# ATtiny828 device description
Architecture: AVR8; Family: tinyAVR
Registers are 8-bit, access not given, no defined reset value unless marked. A register's access mark holds for its fields unless they carry their own. Offsets are from the block's base; [hi:lo] are bit positions; {n}, {i} and the like mark numbered series.

## TC0 (TC8 module) — Timer/Counter, 8-bit
Instances: TC0 0x00
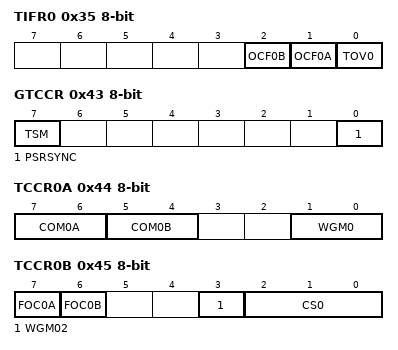
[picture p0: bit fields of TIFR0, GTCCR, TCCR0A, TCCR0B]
0x35 TIFR0 — Timer/Counter0 Interrupt Flag register
  [2] OCF0B — Timer/Counter0 Output Compare Flag 0B
  [1] OCF0A — Timer/Counter0 Output Compare Flag 0A
  [0] TOV0 — Timer/Counter0 Overflow Flag
0x43 GTCCR — General Timer/Counter Control Register
  [7] TSM — Timer/Counter Synchronization Mode
  [0] PSRSYNC — Prescaler Reset Timer/Counter1 and Timer/Counter0
0x44 TCCR0A — Timer/Counter Control Register A
  [7:6] COM0A — Compare Output Mode, Phase Correct PWM Mode
  [5:4] COM0B — Compare Output Mode, Fast PWm
  [1:0] WGM0 — Waveform Generation Mode
0x45 TCCR0B — Timer/Counter Control Register B
  [7] FOC0A — Force Output Compare A
  [6] FOC0B — Force Output Compare B
  [3] WGM02
  [2:0] CS0 — Clock Select
    0=No Clock Source (Stopped); 1=Running, No Prescaling; 2=Running, CLK/8; 3=Running, CLK/64; 4=Running, CLK/256; 5=Running, CLK/1024; 6=Running, ExtClk Tx Falling Edge; 7=Running, ExtClk Tx Rising Edge
0x46 TCNT0 — Timer/Counter0
0x47 OCR0A — Timer/Counter0 Output Compare Register
0x48 OCR0B — Timer/Counter0 Output Compare Register
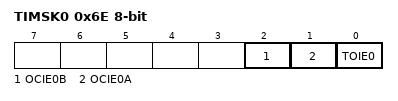
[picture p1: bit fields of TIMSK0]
0x6E TIMSK0 — Timer/Counter0 Interrupt Mask Register
  [2] OCIE0B — Timer/Counter0 Output Compare Match B Interrupt Enable
  [1] OCIE0A — Timer/Counter0 Output Compare Match A Interrupt Enable
  [0] TOIE0 — Timer/Counter0 Overflow Interrupt Enable

## TC1 (TC16 module) — Timer/Counter, 16-bit
Instances: TC1 0x00
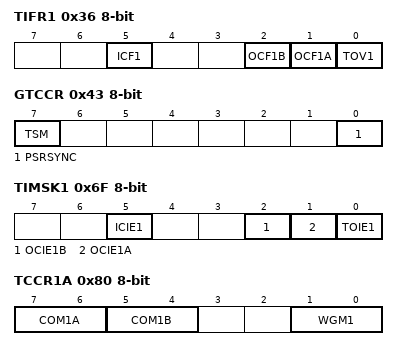
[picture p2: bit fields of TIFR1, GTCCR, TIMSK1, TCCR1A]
0x36 TIFR1 — Timer/Counter Interrupt Flag register
  [5] ICF1 — Input Capture Flag 1
  [2] OCF1B — Output Compare Flag 1B
  [1] OCF1A — Output Compare Flag 1A
  [0] TOV1 — Timer/Counter1 Overflow Flag
0x43 GTCCR — General Timer/Counter Control Register
  [7] TSM — Timer/Counter Synchronization Mode
  [0] PSRSYNC — Prescaler Reset Timer/Counter1 and Timer/Counter0
0x6F TIMSK1 — Timer/Counter Interrupt Mask Register
  [5] ICIE1 — Timer/Counter1 Input Capture Interrupt Enable
  [2] OCIE1B — Timer/Counter1 Output CompareB Match Interrupt Enable
  [1] OCIE1A — Timer/Counter1 Output CompareA Match Interrupt Enable
  [0] TOIE1 — Timer/Counter1 Overflow Interrupt Enable
0x80 TCCR1A — Timer/Counter1 Control Register A
  [7:6] COM1A — Compare Output Mode 1A, bits
  [5:4] COM1B — Compare Output Mode 1B, bits
  [1:0] WGM1 — Waveform Generation Mode
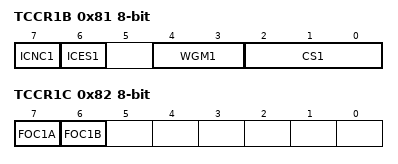
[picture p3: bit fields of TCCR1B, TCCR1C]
0x81 TCCR1B — Timer/Counter1 Control Register B
  [7] ICNC1 — Input Capture 1 Noise Canceler
  [6] ICES1 — Input Capture 1 Edge Select
  [4:3] WGM1 (bit 2 of the value upward) — Waveform Generation Mode
  [2:0] CS1 — Prescaler source of Timer/Counter 1
    0=No Clock Source (Stopped); 1=Running, No Prescaling; 2=Running, CLK/8; 3=Running, CLK/64; 4=Running, CLK/256; 5=Running, CLK/1024; 6=Running, ExtClk Tx Falling Edge; 7=Running, ExtClk Tx Rising Edge
0x82 TCCR1C — Timer/Counter1 Control Register C
  [7] FOC1A, [6] FOC1B
0x84 TCNT1 16-bit — Timer/Counter1 Bytes
0x86 ICR1 16-bit — Timer/Counter1 Input Capture Register Bytes
0x88 OCR1A 16-bit — Timer/Counter1 Output Compare Register Bytes
0x8A OCR1B 16-bit — Timer/Counter1 Output Compare Register Bytes

## TOCPM — Timer/Counter Output Compare Pin
Instances: TOCPM 0x00
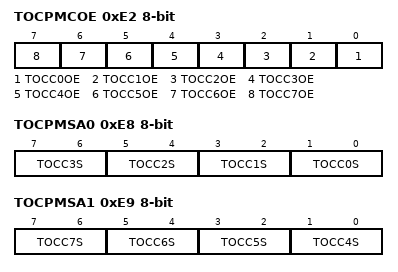
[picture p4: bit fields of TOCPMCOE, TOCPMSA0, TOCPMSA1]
0xE2 TOCPMCOE — Timer Output Compare Pin Mux Channel Output Enable
  [n] TOCC{n}OE (n=0..7) — Timer Output Compare Channel {n} Output Enable
0xE8 TOCPMSA0 — Timer Output Compare Pin Mux Selection 0
  [2n+1:2n] TOCC{n}S (n=0..3) — Timer Output Compare Channel {n} Selection Bits
0xE9 TOCPMSA1 — Timer Output Compare Pin Mux Selection 1
  [2n-7:2n-8] TOCC{n}S (n=4..7) — Timer Output Compare Channel {n} Selection Bits

## ADC — Analog-to-Digital Converter
Instances: ADC 0x00
0x78 ADC 16-bit — ADC Data Register Bytes
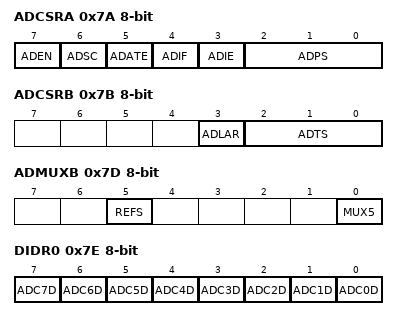
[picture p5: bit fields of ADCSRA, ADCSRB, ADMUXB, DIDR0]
0x7A ADCSRA — The ADC Control and Status register
  [7] ADEN — ADC Enable
  [6] ADSC — ADC Start Conversion
  [5] ADATE — ADC Auto Trigger Enable
  [4] ADIF — ADC Interrupt Flag
  [3] ADIE — ADC Interrupt Enable
  [2:0] ADPS — ADC Prescaler Select Bits
    0=2; 1=2; 2=4; 3=8; 4=16; 5=32; 6=64; 7=128
0x7B ADCSRB — ADC Control and Status Register B
  [3] ADLAR
  [2:0] ADTS — ADC Auto Trigger Sources
    0=Free Running mode; 1=Analog Comparator; 2=External Interrupt Request 0; 3=Timer/Counter0 Compare Match A; 4=Timer/Counter0 Overflow; 5=Timer/Counter1 Compare Match B; 6=Timer/Counter1 Overflow; 7=Timer/Counter1 Capture Event
0x7C ADMUXA — The ADC multiplexer Selection Register A
  [4:0] MUX — Analog Channel Selection Bits 4:0
0x7D ADMUXB — The ADC multiplexer Selection Register B
  [5] REFS — Reference Selection Bit
  [0] MUX5 — Analog Channel Selection Bit 5
0x7E DIDR0 — Digital Input Disable Register 0
  [n] ADC{n}D (n=0..7) — ADC{n} Digital input Disable
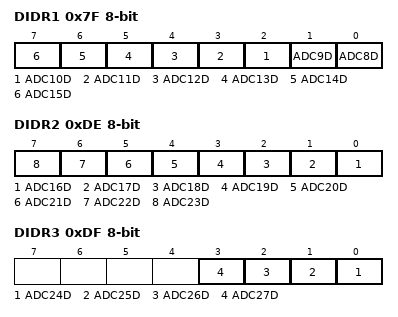
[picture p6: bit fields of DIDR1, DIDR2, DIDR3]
0x7F DIDR1 — Digital Input Disable Register 1
  [n-8] ADC{n}D (n=8..15) — ADC{n} Digital input Disable
0xDE DIDR2 — Digital Input Disable Register 2
  [n-16] ADC{n}D (n=16..23) — ADC{n} Digital input Disable
0xDF DIDR3 — Digital Input Disable Register 2
  [n-24] ADC{n}D (n=24..27) — ADC{n} Digital input Disable
